AUTOSAR XML (schema 4-2-1)
package /MICROSAR/BswM_swc
  mode declaration group ESH_Mode: initial-mode=STARTUP
    5 x mode:
      STARTUP
      RUN
      POSTRUN
      WAKEUP
      SHUTDOWN
  mode declaration group ESH_RunRequest: initial-mode=RELEASED
    mode RELEASED
    mode REQUESTED
  mode declaration group MdgBswMBatteryMode: initial-mode=BSWM_BATTERY_MEDIUM
    mode BSWM_BATTERY_LOW
    mode BSWM_BATTERY_MEDIUM
    mode BSWM_BATTERY_HIGH
  data type mapping set BswMMappingSet  # Contains Mapping for ModeDeclarations Groups which are provided by BswM.
    mode-request-type-maps:
      implementation-data-type=BswM_ESH_Mode, mode-group=ESH_Mode
      implementation-data-type=BswM_ESH_RunRequest, mode-group=ESH_RunRequest
      implementation-data-type=BswM_MdgBswMBatteryMode, mode-group=MdgBswMBatteryMode
package /MICROSAR/BswM_swc/ComponentTypes
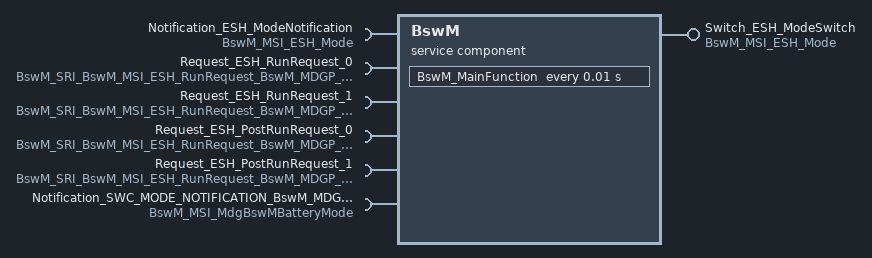
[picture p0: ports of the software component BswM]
  service sw component type BswM: category=SERVICE_COMPONENT
    provide port Switch_ESH_ModeSwitch: provided-interface=BswM_MSI_ESH_Mode
    6 x require port:
      Notification_ESH_ModeNotification: required-interface=BswM_MSI_ESH_Mode
      Request_ESH_RunRequest_0: nonqueued-receiver-com-spec{data-element=requestedMode, handle-out-of-range-status=SILENT, init-value=RELEASED}, required-interface=BswM_SRI_BswM_MSI_ESH_RunRequest_BswM_MDGP_ESH_RunRequest
      Request_ESH_RunRequest_1: nonqueued-receiver-com-spec{data-element=requestedMode, handle-out-of-range-status=SILENT, init-value=RELEASED}, required-interface=BswM_SRI_BswM_MSI_ESH_RunRequest_BswM_MDGP_ESH_RunRequest
      Request_ESH_PostRunRequest_0: nonqueued-receiver-com-spec{data-element=requestedMode, handle-out-of-range-status=SILENT, init-value=RELEASED}, required-interface=BswM_SRI_BswM_MSI_ESH_RunRequest_BswM_MDGP_ESH_RunRequest
      Request_ESH_PostRunRequest_1: nonqueued-receiver-com-spec{data-element=requestedMode, handle-out-of-range-status=SILENT, init-value=RELEASED}, required-interface=BswM_SRI_BswM_MSI_ESH_RunRequest_BswM_MDGP_ESH_RunRequest
      Notification_SWC_MODE_NOTIFICATION_BswM_MDGP_MdgBswMBatteryMode: required-interface=BswM_MSI_MdgBswMBatteryMode
    behavior BswMInternalBehavior: handle-termination-and-restart=NO-SUPPORT, included-data-type-set=data-type=[BswM_ESH_Mode, BswM_ESH_RunRequest, BswM_MdgBswMBatteryMode]
      timing event Timer_BswM_MainFunction: start-on-event=BswM_MainFunction, period=0.01
      port-api-options:
        enable-take-address=true, indirect-api=false, port=Switch_ESH_ModeSwitch
        enable-take-address=true, indirect-api=false, port=Notification_ESH_ModeNotification
        enable-take-address=true, indirect-api=false, port=Request_ESH_RunRequest_0
        enable-take-address=true, indirect-api=false, port=Request_ESH_RunRequest_1
        enable-take-address=true, indirect-api=false, port=Request_ESH_PostRunRequest_0
        enable-take-address=true, indirect-api=false, port=Request_ESH_PostRunRequest_1
        enable-take-address=true, indirect-api=false, port=Notification_SWC_MODE_NOTIFICATION_BswM_MDGP_MdgBswMBatteryMode
      runnable BswM_MainFunction
        data-receive-point-by-arguments:
          4 x access:
            DataReceivePointBswM_MainFunction_Request_ESH_RunRequest_0_requestedMode: accessed-variable=Request_ESH_RunRequest_0.requestedMode
            DataReceivePointBswM_MainFunction_Request_ESH_RunRequest_1_requestedMode: accessed-variable=Request_ESH_RunRequest_1.requestedMode
            DataReceivePointBswM_MainFunction_Request_ESH_PostRunRequest_0_requestedMode: accessed-variable=Request_ESH_PostRunRequest_0.requestedMode
            DataReceivePointBswM_MainFunction_Request_ESH_PostRunRequest_1_requestedMode: accessed-variable=Request_ESH_PostRunRequest_1.requestedMode
        mode-access-points:
          Notification_ESH_ModeNotification.BswM_MDGP_ESH_Mode
          Notification_SWC_MODE_NOTIFICATION_BswM_MDGP_MdgBswMBatteryMode.BswM_MDGP_MdgBswMBatteryMode
        mode switch point ModeSwitchPointBswM_MainFunction_Switch_ESH_ModeSwitch_BswM_MDGP_ESH_Mode: mode-group=Switch_ESH_ModeSwitch.BswM_MDGP_ESH_Mode
  swc implementation BswMImplementation: programming-language=C, behavior=BswMInternalBehavior
package /MICROSAR/BswM_swc/DataTypes
  impl type BswM_ESH_Mode: compu {0=STARTUP, 1=RUN, 2=POSTRUN, 3=WAKEUP, 4=SHUTDOWN}, implementation-data-type=uint8  # Unique value for each user
  impl type BswM_ESH_RunRequest: compu {0=RELEASED, 1=REQUESTED}, implementation-data-type=uint8  # Unique value for each user
  impl type BswM_MdgBswMBatteryMode: compu {0=BSWM_BATTERY_LOW, 1=BSWM_BATTERY_MEDIUM, 2=BSWM_BATTERY_HIGH}, implementation-data-type=uint8  # Unique value for each user
package /MICROSAR/BswM_swc/Interfaces
  mode switch interface BswM_MSI_ESH_Mode: is-service=true, service-kind=BASIC-SOFTWARE-MODE-MANAGER
    mode group BswM_MDGP_ESH_Mode: type=ESH_Mode
  mode switch interface BswM_MSI_ESH_RunRequest: is-service=true, service-kind=BASIC-SOFTWARE-MODE-MANAGER
    mode group BswM_MDGP_ESH_RunRequest: type=ESH_RunRequest
  sender receiver interface BswM_SRI_BswM_MSI_ESH_RunRequest_BswM_MDGP_ESH_RunRequest: is-service=true, service-kind=BASIC-SOFTWARE-MODE-MANAGER
    data requestedMode: type=BswM_ESH_RunRequest
  mode switch interface BswM_MSI_MdgBswMBatteryMode: is-service=true, service-kind=BASIC-SOFTWARE-MODE-MANAGER
    mode group BswM_MDGP_MdgBswMBatteryMode: type=MdgBswMBatteryMode
